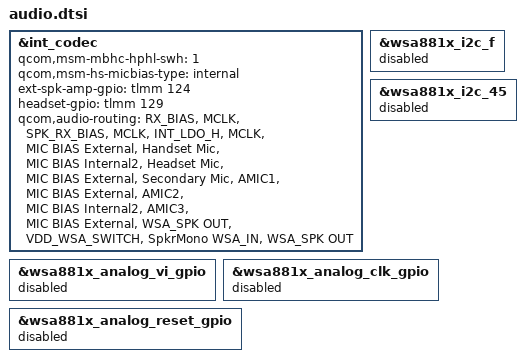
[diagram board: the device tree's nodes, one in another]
/* FROM: santoni-n-oss msm-audio.dtsi+msm8937-audio.dtsi */
&int_codec {
	qcom,msm-mbhc-hphl-swh = <1>;
	qcom,msm-hs-micbias-type = "internal";
	ext-spk-amp-gpio = <&tlmm 124 0>;
	headset-gpio = <&tlmm 129 0>;
	/* FIXME: The change is External2 => Internal2 */
	qcom,audio-routing =
		"RX_BIAS", "MCLK",
		"SPK_RX_BIAS", "MCLK",
		"INT_LDO_H", "MCLK",
		"MIC BIAS External", "Handset Mic",
		"MIC BIAS Internal2", "Headset Mic",
		"MIC BIAS External", "Secondary Mic",
		"AMIC1", "MIC BIAS External",
		"AMIC2", "MIC BIAS Internal2",
		"AMIC3", "MIC BIAS External",
		"WSA_SPK OUT", "VDD_WSA_SWITCH",
		"SpkrMono WSA_IN", "WSA_SPK OUT";
};

/* Disable unused wsa881x i2c nodes */
&wsa881x_i2c_f {
        status = "disabled";
};

&wsa881x_i2c_45 {
        status = "disabled";
};

&wsa881x_analog_vi_gpio {
        status = "disabled";
};

&wsa881x_analog_clk_gpio {
        status = "disabled";
};

&wsa881x_analog_reset_gpio {
        status = "disabled";
};
